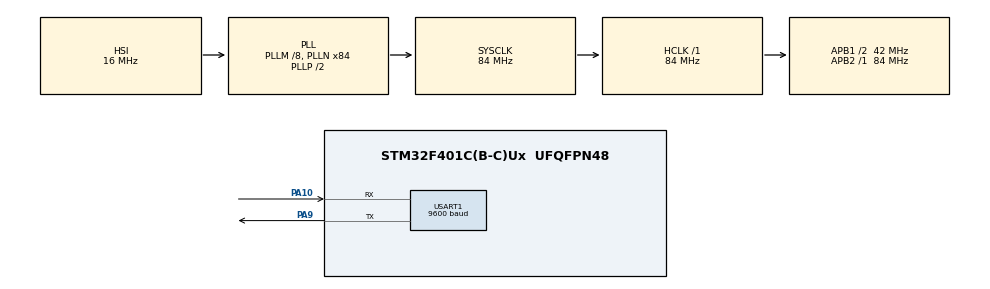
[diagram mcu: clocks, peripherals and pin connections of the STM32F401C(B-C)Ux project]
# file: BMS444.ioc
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Mcu.Family=STM32F4
Mcu.Name=STM32F401C(B-C)Ux
Mcu.Package=UFQFPN48
NVIC.PriorityGroup=NVIC_PRIORITYGROUP_4
PA10.Mode=Asynchronous
PA10.Signal=USART1_RX
PA13.Mode=Serial_Wire
PA13.Signal=SYS_JTMS-SWDIO
PA14.Mode=Serial_Wire
PA14.Signal=SYS_JTCK-SWCLK
PA9.Mode=Asynchronous
PA9.Signal=USART1_TX
ProjectManager.HeapSize=0x200
ProjectManager.StackSize=0x400
ProjectManager.TargetToolchain=STM32CubeIDE
RCC.48MHZClocksFreq_Value=42000000
RCC.AHBFreq_Value=84000000
RCC.APB1CLKDivider=RCC_HCLK_DIV2
RCC.APB1Freq_Value=42000000
RCC.APB1TimFreq_Value=84000000
RCC.APB2Freq_Value=84000000
RCC.APB2TimFreq_Value=84000000
RCC.CortexFreq_Value=84000000
RCC.HCLKFreq_Value=84000000
RCC.HSE_VALUE=25000000
RCC.HSI_VALUE=16000000
RCC.LSE_VALUE=32768
RCC.PLLM=8
RCC.PLLN=84
RCC.SYSCLKFreq_VALUE=84000000
RCC.SYSCLKSource=RCC_SYSCLKSOURCE_PLLCLK
RCC.VCOOutputFreq_Value=168000000
USART1.BaudRate=9600
USART1.VirtualMode=VM_ASYNC
board=custom

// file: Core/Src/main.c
/* USER CODE BEGIN Header */
/**
  ******************************************************************************
  * @file           : main.c
  * @brief          : Main program body
  ******************************************************************************
  * @attention
  *
  * Copyright (c) 2024 STMicroelectronics.
  * All rights reserved.
  *
  * This software is licensed under terms that can be found in the LICENSE file
  * in the root directory of this software component.
  * If no LICENSE file comes with this software, it is provided AS-IS.
  *
  ******************************************************************************
  */
/* USER CODE END Header */
#include "main.h"

/* USER CODE BEGIN PD */
#define BMS_ADDRESS  0x80  // Upper computer address
#define BAUD_RATE     9600
#define UART_INSTANCE &huart1  // Replace with your specific UART instance

// Data ID definitions
#define DATA_ID_SOC_CURRENT          0x90
#define DATA_ID_MAX_MIN_VOLTAGE      0x91
#define DATA_ID_MAX_MIN_TEMPERATURE  0x92
#define DATA_ID_CHARGE_DISCHARGE_MOS 0x93
#define DATA_ID_STATUS_INFO_1         0x94
#define DATA_ID_CELL_VOLTAGE         0x95
#define DATA_ID_CELL_TEMPERATURE     0x96
#define DATA_ID_CELL_BALANCE_STATE    0x97
#define DATA_ID_BATTERY_FAILURE      0x98
/* USER CODE END PD */

UART_HandleTypeDef huart1;

void SystemClock_Config(void);
static void MX_GPIO_Init(void);
static void MX_USART1_UART_Init(void);
/* USER CODE BEGIN PFP */
void send_daly_command(uint8_t data_id, uint8_t data[]);
uint8_t receive_daly_data(uint8_t expected_data_id, uint8_t data[], uint8_t data_length);
void convert_data(uint8_t raw_data[], float ret_data[]);
/* USER CODE END PFP */

/* USER CODE BEGIN 0 */
uint8_t received_data[8];
float decrypt_data[4];
/* USER CODE END 0 */

int main(void)
{

  /* MCU Configuration--------------------------------------------------------*/

  /* Reset of all peripherals, Initializes the Flash interface and the Systick. */
  HAL_Init();

  /* Configure the system clock */
  SystemClock_Config();

  /* Initialize all configured peripherals */
  MX_GPIO_Init();
  MX_USART1_UART_Init();
  /* USER CODE BEGIN 2 */

    // Read SOC and current
    uint8_t soc_current_data[8] = {0};
  /* USER CODE END 2 */

  /* Infinite loop */
  /* USER CODE BEGIN WHILE */
  while (1)
  {
	  send_daly_command(DATA_ID_SOC_CURRENT, soc_current_data);
	  receive_daly_data(DATA_ID_SOC_CURRENT, received_data, 8);

	  convert_data(received_data, decrypt_data); // decrypt_data[0] - voltage (V)
	  	  	  	  	  	  	  	  	  	  	  	 // decrypt_data[1] - acquisition voltage
												 // decrypt_data[2] - current strength (A)
												 // decrypt_data[3] - SOC (%)
    /* USER CODE END WHILE */

  }
}

void SystemClock_Config(void)
{
  RCC_OscInitTypeDef RCC_OscInitStruct = {0};
  RCC_ClkInitTypeDef RCC_ClkInitStruct = {0};

  /** Configure the main internal regulator output voltage
  */
  __HAL_RCC_PWR_CLK_ENABLE();
  __HAL_PWR_VOLTAGESCALING_CONFIG(PWR_REGULATOR_VOLTAGE_SCALE2);

  /** Initializes the RCC Oscillators according to the specified parameters
  * in the RCC_OscInitTypeDef structure.
  */
  RCC_OscInitStruct.OscillatorType = RCC_OSCILLATORTYPE_HSI;
  RCC_OscInitStruct.HSIState = RCC_HSI_ON;
  RCC_OscInitStruct.HSICalibrationValue = RCC_HSICALIBRATION_DEFAULT;
  RCC_OscInitStruct.PLL.PLLState = RCC_PLL_ON;
  RCC_OscInitStruct.PLL.PLLSource = RCC_PLLSOURCE_HSI;
  RCC_OscInitStruct.PLL.PLLM = 8;
  RCC_OscInitStruct.PLL.PLLN = 84;
  RCC_OscInitStruct.PLL.PLLP = RCC_PLLP_DIV2;
  RCC_OscInitStruct.PLL.PLLQ = 4;
  if (HAL_RCC_OscConfig(&RCC_OscInitStruct) != HAL_OK)
  {
    Error_Handler();
  }

  /** Initializes the CPU, AHB and APB buses clocks
  */
  RCC_ClkInitStruct.ClockType = RCC_CLOCKTYPE_HCLK|RCC_CLOCKTYPE_SYSCLK
                              |RCC_CLOCKTYPE_PCLK1|RCC_CLOCKTYPE_PCLK2;
  RCC_ClkInitStruct.SYSCLKSource = RCC_SYSCLKSOURCE_PLLCLK;
  RCC_ClkInitStruct.AHBCLKDivider = RCC_SYSCLK_DIV1;
  RCC_ClkInitStruct.APB1CLKDivider = RCC_HCLK_DIV2;
  RCC_ClkInitStruct.APB2CLKDivider = RCC_HCLK_DIV1;

  if (HAL_RCC_ClockConfig(&RCC_ClkInitStruct, FLASH_LATENCY_2) != HAL_OK)
  {
    Error_Handler();
  }
}

static void MX_USART1_UART_Init(void)
{

  huart1.Instance = USART1;
  huart1.Init.BaudRate = 9600;
  huart1.Init.WordLength = UART_WORDLENGTH_8B;
  huart1.Init.StopBits = UART_STOPBITS_1;
  huart1.Init.Parity = UART_PARITY_NONE;
  huart1.Init.Mode = UART_MODE_TX_RX;
  huart1.Init.HwFlowCtl = UART_HWCONTROL_NONE;
  huart1.Init.OverSampling = UART_OVERSAMPLING_16;
  if (HAL_UART_Init(&huart1) != HAL_OK)
  {
    Error_Handler();
  }

}

static void MX_GPIO_Init(void)
{

  /* GPIO Ports Clock Enable */
  __HAL_RCC_GPIOA_CLK_ENABLE();

}

/* USER CODE BEGIN 4 */
void send_daly_command(uint8_t data_id, uint8_t data[]) {
  uint8_t tx_buffer[13];
  tx_buffer[0] = 0xA5;  // Start flag
  tx_buffer[1] = BMS_ADDRESS;
  tx_buffer[2] = data_id;
  tx_buffer[3] = 0x08;  // Data length (fixed)
  // Copy data bytes (modify for specific data)
  for (int i = 0; i < 8; i++) {
    tx_buffer[4 + i] = data[i];
  }
  uint8_t checksum = 0;
  for (int i = 0; i < 12; i++) {
    checksum += tx_buffer[i];
  }
  tx_buffer[12] = checksum;

  HAL_UART_Transmit(UART_INSTANCE, tx_buffer, sizeof(tx_buffer), 24);
}

uint8_t receive_daly_data(uint8_t expected_data_id, uint8_t data[], uint8_t data_length) {
  uint8_t rx_buffer[13];
  if (HAL_UART_Receive(UART_INSTANCE, rx_buffer, sizeof(rx_buffer), 100) != HAL_OK) {
    return 1;  // Error receiving data
  }

  // Copy received data
  for (int i = 0; i < data_length; i++) {
    data[i] = rx_buffer[4 + i];
  }

  return 0;  // Success
}

void convert_data(uint8_t raw_data[], float ret_data[]){
	ret_data[0] = ((raw_data[0] << 8) | raw_data[1]) / 10.0;
	ret_data[1] = (raw_data[2] << 8) | raw_data[3];
	ret_data[2] = ((raw_data[4] << 8) | raw_data[5]) - 30000;
	ret_data[3] = ((raw_data[6] << 8) | raw_data[7]) / 10.0;
}
/* USER CODE END 4 */

void Error_Handler(void)
{
  __disable_irq();
  while (1)
  {
  }
}
